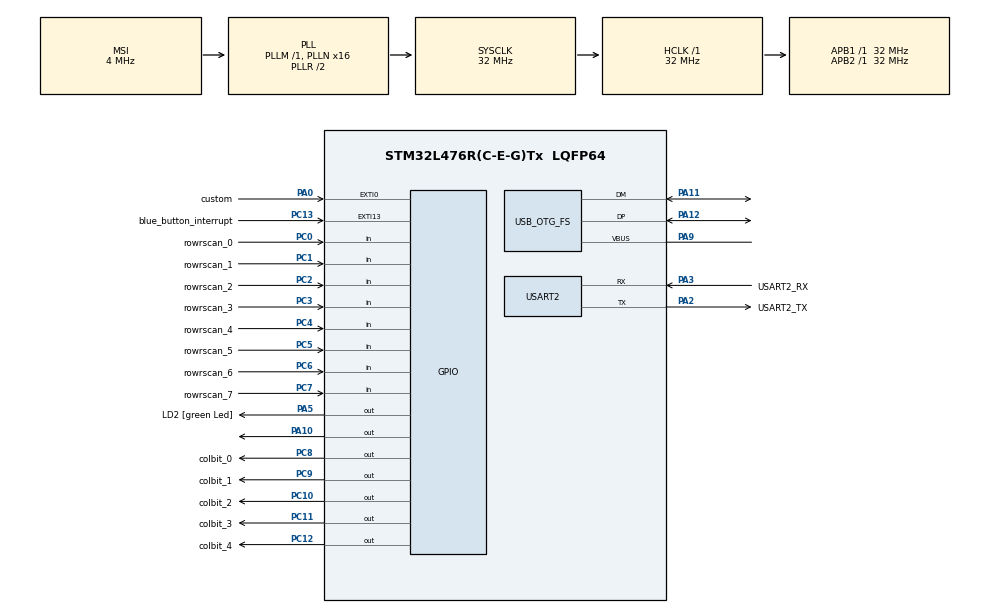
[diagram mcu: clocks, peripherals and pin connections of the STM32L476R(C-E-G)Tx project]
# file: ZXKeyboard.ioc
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FREERTOS.Tasks01=defaultTask,0,128,StartDefaultTask,Default,NULL,Dynamic,NULL,NULL;keuscan,-3,128,keuscan_process,Default,NULL,Static,keuscan_buffer,keuscan_control_block
Mcu.Family=STM32L4
Mcu.Name=STM32L476R(C-E-G)Tx
Mcu.Package=LQFP64
NVIC.EXTI0_IRQn=true\:0\:0\:false\:false\:true\:false\:true\:true
NVIC.EXTI15_10_IRQn=true\:0\:0\:false\:false\:true\:false\:true\:true
NVIC.OTG_FS_IRQn=true\:0\:0\:false\:false\:true\:false\:false\:true
NVIC.PriorityGroup=NVIC_PRIORITYGROUP_4
NVIC.TIM1_UP_TIM16_IRQn=true\:0\:0\:false\:false\:true\:false\:false\:true
NVIC.TimeBase=TIM1_UP_TIM16_IRQn
NVIC.TimeBaseIP=TIM1
PA0.GPIO_Label=custom
PA0.GPIO_ModeDefaultEXTI=GPIO_MODE_IT_FALLING
PA0.GPIO_PuPd=GPIO_PULLUP
PA0.Signal=GPXTI0
PA10.Signal=GPIO_Output
PA11.Mode=Host_Only
PA11.Signal=USB_OTG_FS_DM
PA12.Mode=Host_Only
PA12.Signal=USB_OTG_FS_DP
PA13\ (JTMS-SWDIO).GPIO_Label=TMS
PA13\ (JTMS-SWDIO).Mode=Serial_Wire
PA13\ (JTMS-SWDIO).Signal=SYS_JTMS-SWDIO
PA14\ (JTCK-SWCLK).GPIO_Label=TCK
PA14\ (JTCK-SWCLK).Mode=Serial_Wire
PA14\ (JTCK-SWCLK).Signal=SYS_JTCK-SWCLK
PA2.GPIO_Label=USART2_TX
PA2.GPIO_Mode=GPIO_MODE_AF_PP
PA2.GPIO_PuPd=GPIO_NOPULL
PA2.GPIO_Speed=GPIO_SPEED_FREQ_VERY_HIGH
PA2.Mode=Asynchronous
PA2.Signal=USART2_TX
PA3.GPIO_Label=USART2_RX
PA3.GPIO_Mode=GPIO_MODE_AF_PP
PA3.GPIO_PuPd=GPIO_NOPULL
PA3.GPIO_Speed=GPIO_SPEED_FREQ_VERY_HIGH
PA3.Mode=Asynchronous
PA3.Signal=USART2_RX
PA5.GPIO_Label=LD2 [green Led]
PA5.GPIO_ModeDefaultOutputPP=GPIO_MODE_OUTPUT_PP
PA5.GPIO_PuPd=GPIO_NOPULL
PA5.GPIO_Speed=GPIO_SPEED_FREQ_LOW
PA5.Signal=GPIO_Output
PA9.Mode=Activate_VBUS
PA9.Signal=USB_OTG_FS_VBUS
PB3\ (JTDO-TRACESWO).GPIO_Label=SWO
PB3\ (JTDO-TRACESWO).Signal=SYS_JTDO-SWO
PC0.GPIO_Label=rowrscan_0
PC0.GPIO_PuPd=GPIO_PULLUP
PC0.Signal=GPIO_Input
PC1.GPIO_Label=rowrscan_1
PC1.GPIO_PuPd=GPIO_PULLUP
PC1.Signal=GPIO_Input
PC10.GPIO_Label=colbit_2
PC10.Signal=GPIO_Output
PC11.GPIO_Label=colbit_3
PC11.Signal=GPIO_Output
PC12.GPIO_Label=colbit_4
PC12.Signal=GPIO_Output
PC13.GPIO_Label=blue_button_interrupt
PC13.GPIO_ModeDefaultEXTI=GPIO_MODE_IT_FALLING
PC13.GPIO_PuPd=GPIO_PULLUP
PC13.Signal=GPXTI13
PC14-OSC32_IN\ (PC14).Mode=LSE-External-Oscillator
PC14-OSC32_IN\ (PC14).Signal=RCC_OSC32_IN
PC15-OSC32_OUT\ (PC15).Mode=LSE-External-Oscillator
PC15-OSC32_OUT\ (PC15).Signal=RCC_OSC32_OUT
PC2.GPIO_Label=rowrscan_2
PC2.GPIO_PuPd=GPIO_PULLUP
PC2.Signal=GPIO_Input
PC3.GPIO_Label=rowrscan_3
PC3.GPIO_PuPd=GPIO_PULLUP
PC3.Signal=GPIO_Input
PC4.GPIO_Label=rowrscan_4
PC4.GPIO_PuPd=GPIO_PULLUP
PC4.Signal=GPIO_Input
PC5.GPIO_Label=rowrscan_5
PC5.GPIO_PuPd=GPIO_PULLUP
PC5.Signal=GPIO_Input
PC6.GPIO_Label=rowrscan_6
PC6.GPIO_PuPd=GPIO_PULLUP
PC6.Signal=GPIO_Input
PC7.GPIO_Label=rowrscan_7
PC7.GPIO_PuPd=GPIO_PULLUP
PC7.Signal=GPIO_Input
PC8.GPIO_Label=colbit_0
PC8.Signal=GPIO_Output
PC9.GPIO_Label=colbit_1
PC9.Signal=GPIO_Output
PH0-OSC_IN\ (PH0).Signal=RCC_OSC_IN
PH1-OSC_OUT\ (PH1).Signal=RCC_OSC_OUT
ProjectManager.HeapSize=0x200
ProjectManager.StackSize=0x400
ProjectManager.TargetToolchain=STM32CubeIDE
RCC.ADCFreq_Value=48000000
RCC.AHBFreq_Value=32000000
RCC.APB1Freq_Value=32000000
RCC.APB1TimFreq_Value=32000000
RCC.APB2Freq_Value=32000000
RCC.APB2TimFreq_Value=32000000
RCC.CortexFreq_Value=32000000
RCC.HCLKFreq_Value=32000000
RCC.HSE_VALUE=8000000
RCC.HSI_VALUE=16000000
RCC.MSI_VALUE=4000000
RCC.PLLN=16
RCC.PLLSAI1N=24
RCC.SYSCLKFreq_VALUE=32000000
RCC.SYSCLKSource=RCC_SYSCLKSOURCE_PLLCLK
RCC.USBFreq_Value=48000000
RCC.VCOOutputFreq_Value=64000000
USART2.VirtualMode-Asynchronous=VM_ASYNC
USB_HOST.BSP.number=1
USB_HOST.USBH_HandleTypeDef=hUsbHostFS
USB_HOST.VirtualModeFS=Hid
USB_HOST0.BSP.STBoard=false
USB_HOST0.BSP.api=Unknown
USB_HOST0.BSP.i2caddr=0
USB_HOST0.BSP.instance=PA10
USB_HOST0.BSP.ip=GPIO
USB_HOST0.BSP.mode=Output
USB_HOST0.BSP.name=Drive_VBUS_FS
USB_HOST0.BSP.solution=PA10
USB_OTG_FS.VirtualMode=Host_Only
USB_OTG_FS.phy_itface=HCD_PHY_EMBEDDED
VP_FREERTOS_VS_CMSIS_V1.Mode=CMSIS_V1
VP_SYS_VS_tim1.Mode=TIM1
VP_USB_HOST_VS_USB_HOST_HID_FS.Mode=HID_FS
board=NUCLEO-L476RG

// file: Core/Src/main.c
/* USER CODE BEGIN Header */
/**
  ******************************************************************************
  * @file           : main.c
  * @brief          : Main program body
  ******************************************************************************
  * @attention
  *
  * <h2><center>&copy; Copyright (c) 2020 STMicroelectronics.
  * All rights reserved.</center></h2>
  *
  * This software component is licensed by ST under BSD 3-Clause license,
  * the "License"; You may not use this file except in compliance with the
  * License. You may obtain a copy of the License at:
  *                        opensource.org/licenses/BSD-3-Clause
  *
  ******************************************************************************
  */
/* USER CODE END Header */
#include "main.h"
#include "cmsis_os.h"
#include "usb_host.h"

/* USER CODE BEGIN Includes */
#include "interupt.h"
/* USER CODE END Includes */

UART_HandleTypeDef huart2;

osThreadId defaultTaskHandle;
osThreadId keuscanHandle;
uint32_t keuscan_buffer[ 128 ];
osStaticThreadDef_t keuscan_control_block;

void SystemClock_Config(void);
static void MX_GPIO_Init(void);
static void MX_USART2_UART_Init(void);
void StartDefaultTask(void const * argument);
void keuscan_process(void const * argument);

int main(void)
{

  /* MCU Configuration--------------------------------------------------------*/

  /* Reset of all peripherals, Initializes the Flash interface and the Systick. */
  HAL_Init();

  /* Configure the system clock */
  SystemClock_Config();

  /* Initialize all configured peripherals */
  MX_GPIO_Init();
  MX_USART2_UART_Init();

  /* Create the thread(s) */
  /* definition and creation of defaultTask */
  osThreadDef(defaultTask, StartDefaultTask, osPriorityNormal, 0, 128);
  defaultTaskHandle = osThreadCreate(osThread(defaultTask), NULL);

  /* definition and creation of keuscan */
  osThreadStaticDef(keuscan, keuscan_process, osPriorityIdle, 0, 128, keuscan_buffer, &keuscan_control_block);
  keuscanHandle = osThreadCreate(osThread(keuscan), NULL);

  /* Start scheduler */
  osKernelStart();

  /* We should never get here as control is now taken by the scheduler */
  /* Infinite loop */
  while (1)
  {

  }
}

void SystemClock_Config(void)
{
  RCC_OscInitTypeDef RCC_OscInitStruct = {0};
  RCC_ClkInitTypeDef RCC_ClkInitStruct = {0};
  RCC_PeriphCLKInitTypeDef PeriphClkInit = {0};

  /** Configure LSE Drive Capability
  */
  HAL_PWR_EnableBkUpAccess();
  __HAL_RCC_LSEDRIVE_CONFIG(RCC_LSEDRIVE_LOW);
  /** Initializes the RCC Oscillators according to the specified parameters
  * in the RCC_OscInitTypeDef structure.
  */
  RCC_OscInitStruct.OscillatorType = RCC_OSCILLATORTYPE_LSE|RCC_OSCILLATORTYPE_MSI;
  RCC_OscInitStruct.LSEState = RCC_LSE_ON;
  RCC_OscInitStruct.MSIState = RCC_MSI_ON;
  RCC_OscInitStruct.MSICalibrationValue = 0;
  RCC_OscInitStruct.MSIClockRange = RCC_MSIRANGE_6;
  RCC_OscInitStruct.PLL.PLLState = RCC_PLL_ON;
  RCC_OscInitStruct.PLL.PLLSource = RCC_PLLSOURCE_MSI;
  RCC_OscInitStruct.PLL.PLLM = 1;
  RCC_OscInitStruct.PLL.PLLN = 16;
  RCC_OscInitStruct.PLL.PLLP = RCC_PLLP_DIV7;
  RCC_OscInitStruct.PLL.PLLQ = RCC_PLLQ_DIV2;
  RCC_OscInitStruct.PLL.PLLR = RCC_PLLR_DIV2;
  if (HAL_RCC_OscConfig(&RCC_OscInitStruct) != HAL_OK)
  {
    Error_Handler();
  }
  /** Initializes the CPU, AHB and APB buses clocks
  */
  RCC_ClkInitStruct.ClockType = RCC_CLOCKTYPE_HCLK|RCC_CLOCKTYPE_SYSCLK
                              |RCC_CLOCKTYPE_PCLK1|RCC_CLOCKTYPE_PCLK2;
  RCC_ClkInitStruct.SYSCLKSource = RCC_SYSCLKSOURCE_PLLCLK;
  RCC_ClkInitStruct.AHBCLKDivider = RCC_SYSCLK_DIV1;
  RCC_ClkInitStruct.APB1CLKDivider = RCC_HCLK_DIV1;
  RCC_ClkInitStruct.APB2CLKDivider = RCC_HCLK_DIV1;

  if (HAL_RCC_ClockConfig(&RCC_ClkInitStruct, FLASH_LATENCY_1) != HAL_OK)
  {
    Error_Handler();
  }
  PeriphClkInit.PeriphClockSelection = RCC_PERIPHCLK_USART2|RCC_PERIPHCLK_USB;
  PeriphClkInit.Usart2ClockSelection = RCC_USART2CLKSOURCE_PCLK1;
  PeriphClkInit.UsbClockSelection = RCC_USBCLKSOURCE_PLLSAI1;
  PeriphClkInit.PLLSAI1.PLLSAI1Source = RCC_PLLSOURCE_MSI;
  PeriphClkInit.PLLSAI1.PLLSAI1M = 1;
  PeriphClkInit.PLLSAI1.PLLSAI1N = 24;
  PeriphClkInit.PLLSAI1.PLLSAI1P = RCC_PLLP_DIV7;
  PeriphClkInit.PLLSAI1.PLLSAI1Q = RCC_PLLQ_DIV2;
  PeriphClkInit.PLLSAI1.PLLSAI1R = RCC_PLLR_DIV2;
  PeriphClkInit.PLLSAI1.PLLSAI1ClockOut = RCC_PLLSAI1_48M2CLK;
  if (HAL_RCCEx_PeriphCLKConfig(&PeriphClkInit) != HAL_OK)
  {
    Error_Handler();
  }
  /** Configure the main internal regulator output voltage
  */
  if (HAL_PWREx_ControlVoltageScaling(PWR_REGULATOR_VOLTAGE_SCALE1) != HAL_OK)
  {
    Error_Handler();
  }
  /** Enable MSI Auto calibration
  */
  HAL_RCCEx_EnableMSIPLLMode();
}

static void MX_USART2_UART_Init(void)
{

  huart2.Instance = USART2;
  huart2.Init.BaudRate = 115200;
  huart2.Init.WordLength = UART_WORDLENGTH_8B;
  huart2.Init.StopBits = UART_STOPBITS_1;
  huart2.Init.Parity = UART_PARITY_NONE;
  huart2.Init.Mode = UART_MODE_TX_RX;
  huart2.Init.HwFlowCtl = UART_HWCONTROL_NONE;
  huart2.Init.OverSampling = UART_OVERSAMPLING_16;
  huart2.Init.OneBitSampling = UART_ONE_BIT_SAMPLE_DISABLE;
  huart2.AdvancedInit.AdvFeatureInit = UART_ADVFEATURE_NO_INIT;
  if (HAL_UART_Init(&huart2) != HAL_OK)
  {
    Error_Handler();
  }

}

static void MX_GPIO_Init(void)
{
  GPIO_InitTypeDef GPIO_InitStruct = {0};

  /* GPIO Ports Clock Enable */
  __HAL_RCC_GPIOC_CLK_ENABLE();
  __HAL_RCC_GPIOH_CLK_ENABLE();
  __HAL_RCC_GPIOA_CLK_ENABLE();
  __HAL_RCC_GPIOB_CLK_ENABLE();

  /*Configure GPIO pin Output Level */
  HAL_GPIO_WritePin(GPIOA, LD2_Pin|GPIO_PIN_10, GPIO_PIN_RESET);

  /*Configure GPIO pin Output Level */
  HAL_GPIO_WritePin(GPIOC, colbit_0_Pin|colbit_1_Pin|colbit_2_Pin|colbit_3_Pin
                          |colbit_4_Pin, GPIO_PIN_RESET);

  /*Configure GPIO pin : blue_button_interrupt_Pin */
  GPIO_InitStruct.Pin = blue_button_interrupt_Pin;
  GPIO_InitStruct.Mode = GPIO_MODE_IT_FALLING;
  GPIO_InitStruct.Pull = GPIO_PULLUP;
  HAL_GPIO_Init(blue_button_interrupt_GPIO_Port, &GPIO_InitStruct);

  /*Configure GPIO pins : rowrscan_0_Pin rowrscan_1_Pin rowrscan_2_Pin rowrscan_3_Pin
                           rowrscan_4_Pin rowrscan_5_Pin rowrscan_6_Pin rowrscan_7_Pin */
  GPIO_InitStruct.Pin = rowrscan_0_Pin|rowrscan_1_Pin|rowrscan_2_Pin|rowrscan_3_Pin
                          |rowrscan_4_Pin|rowrscan_5_Pin|rowrscan_6_Pin|rowrscan_7_Pin;
  GPIO_InitStruct.Mode = GPIO_MODE_INPUT;
  GPIO_InitStruct.Pull = GPIO_PULLUP;
  HAL_GPIO_Init(GPIOC, &GPIO_InitStruct);

  /*Configure GPIO pin : custom_Pin */
  GPIO_InitStruct.Pin = custom_Pin;
  GPIO_InitStruct.Mode = GPIO_MODE_IT_FALLING;
  GPIO_InitStruct.Pull = GPIO_PULLUP;
  HAL_GPIO_Init(custom_GPIO_Port, &GPIO_InitStruct);

  /*Configure GPIO pins : LD2_Pin PA10 */
  GPIO_InitStruct.Pin = LD2_Pin|GPIO_PIN_10;
  GPIO_InitStruct.Mode = GPIO_MODE_OUTPUT_PP;
  GPIO_InitStruct.Pull = GPIO_NOPULL;
  GPIO_InitStruct.Speed = GPIO_SPEED_FREQ_LOW;
  HAL_GPIO_Init(GPIOA, &GPIO_InitStruct);

  /*Configure GPIO pins : colbit_0_Pin colbit_1_Pin colbit_2_Pin colbit_3_Pin
                           colbit_4_Pin */
  GPIO_InitStruct.Pin = colbit_0_Pin|colbit_1_Pin|colbit_2_Pin|colbit_3_Pin
                          |colbit_4_Pin;
  GPIO_InitStruct.Mode = GPIO_MODE_OUTPUT_PP;
  GPIO_InitStruct.Pull = GPIO_NOPULL;
  GPIO_InitStruct.Speed = GPIO_SPEED_FREQ_LOW;
  HAL_GPIO_Init(GPIOC, &GPIO_InitStruct);

  /* EXTI interrupt init*/
  HAL_NVIC_SetPriority(EXTI0_IRQn, 0, 0);
  HAL_NVIC_EnableIRQ(EXTI0_IRQn);

  HAL_NVIC_SetPriority(EXTI15_10_IRQn, 0, 0);
  HAL_NVIC_EnableIRQ(EXTI15_10_IRQn);

}

void StartDefaultTask(void const * argument)
{
  /* init code for USB_HOST */
  MX_USB_HOST_Init();
  for(;;)
  {
    osDelay(1);
  }
}

void keuscan_process(void const * argument)
{
  /* USER CODE BEGIN keuscan_process */
  /* Infinite loop */
  for(;;)
  {
    osDelay(get_delay());
    HAL_GPIO_WritePin(LD2_GPIO_Port, LD2_Pin, GPIO_PIN_SET);
    osDelay(get_delay());
    HAL_GPIO_WritePin(LD2_GPIO_Port, LD2_Pin, GPIO_PIN_RESET);
  }
  /* USER CODE END keuscan_process */
}

void HAL_TIM_PeriodElapsedCallback(TIM_HandleTypeDef *htim)
{
  if (htim->Instance == TIM1) {
    HAL_IncTick();
  }
}

void Error_Handler(void)
{
}

/************************ (C) COPYRIGHT STMicroelectronics *****END OF FILE****/
